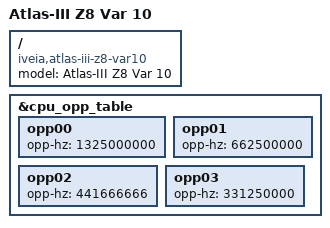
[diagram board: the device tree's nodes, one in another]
#include <machine/atlas-iii-z8.dtsi>

/ {
    model = "Atlas-III Z8 Var 10";
    compatible = "iveia,atlas-iii-z8-var10", "iveia,atlas-iii-z8", "iveia,atlas-z8", "xlnx,zynqmp";
};

/*
 * See atlas-iii-z8.dtsi - for Var 10, this is a speed -2 device, with APLL set
 * to 1325MHz
 */
&cpu_opp_table {
    opp00 {
        opp-hz = /bits/ 64 <1325000000>;
    };

    opp01 {
        opp-hz = /bits/ 64 <662500000>;
    };

    opp02 {
        opp-hz = /bits/ 64 <441666666>;
    };

    opp03 {
        opp-hz = /bits/ 64 <331250000>;
    };
};


